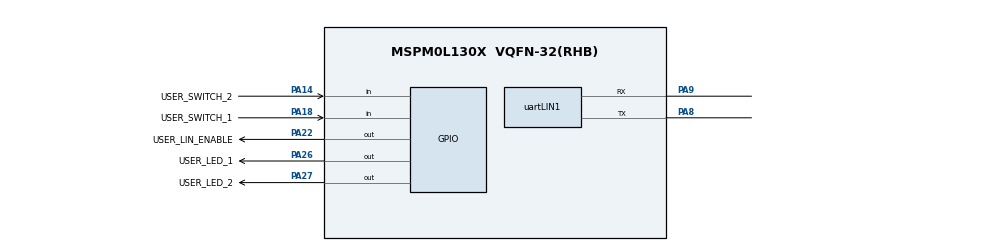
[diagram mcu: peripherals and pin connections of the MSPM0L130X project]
// @cliArgs --device "MSPM0L130X" --package "VQFN-32(RHB)" --part "Default"
// @cliArgs --board /ti/boards/LP_MSPM0L1306 --rtos nortos

/**
 * Import the modules used in this configuration.
 */
const Board  = scripting.addModule("/ti/driverlib/Board");
const GPIO   = scripting.addModule("/ti/driverlib/GPIO", {}, false);
const GPIO1  = GPIO.addInstance();
const GPIO2  = GPIO.addInstance();
const GPIO3  = GPIO.addInstance();
const uartLIN    = scripting.addModule("/ti/driverlib/uartLIN", {}, false);
const uartLIN1   = uartLIN.addInstance();
const SYSCTL = scripting.addModule("/ti/driverlib/SYSCTL");

/**
 * Write custom configuration values to the imported modules.
 */

GPIO1.$name                         = "GPIO_LEDS";
GPIO1.portSegment                   = "Upper";
GPIO1.port                          = "PORTA";
GPIO1.associatedPins.create(2);
GPIO1.associatedPins[0].$name       = "USER_LED_1";
GPIO1.associatedPins[0].assignedPin = "26";
GPIO1.associatedPins[0].pin.$assign = "PA26";
GPIO1.associatedPins[1].$name       = "USER_LED_2";
GPIO1.associatedPins[1].assignedPin = "27";
GPIO1.associatedPins[1].pin.$assign = "PA27";

GPIO2.$name                                 = "GPIO_LIN_ENABLE";
GPIO2.port                                  = "PORTA";
GPIO2.associatedPins[0].$name               = "USER_LIN_ENABLE";
GPIO2.associatedPins[0].assignedPin         = "22";
GPIO2.associatedPins[0].assignedPortSegment = "Upper";
GPIO2.associatedPins[0].pin.$assign         = "PA22";

GPIO3.$name                                 = "GPIO_SWITCHES1";
GPIO3.port                                  = "PORTA";
GPIO3.associatedPins.create(2);
GPIO3.associatedPins[0].$name               = "USER_SWITCH_1";
GPIO3.associatedPins[0].assignedPortSegment = "Upper";
GPIO3.associatedPins[0].assignedPin         = "18";
GPIO3.associatedPins[0].direction           = "INPUT";
GPIO3.associatedPins[0].interruptEn         = true;
GPIO3.associatedPins[0].polarity            = "RISE";
GPIO3.associatedPins[0].pin.$assign         = "PA18";
GPIO3.associatedPins[1].$name               = "USER_SWITCH_2";
GPIO3.associatedPins[1].assignedPin         = "14";
GPIO3.associatedPins[1].assignedPortSegment = "Lower";
GPIO3.associatedPins[1].direction           = "INPUT";
GPIO3.associatedPins[1].interruptEn         = true;
GPIO3.associatedPins[1].internalResistor    = "PULL_UP";
GPIO3.associatedPins[1].polarity            = "FALL";
GPIO3.associatedPins[1].pin.$assign         = "PA14";

uartLIN1.$name                    = "LIN_0";
uartLIN1.targetBaudRate           = 19200;
uartLIN1.tbitVal                  = 9.5;
uartLIN1.enableDMARX              = false;
uartLIN1.enableDMATX              = false;
uartLIN1.enabledInterrupts        = ["RX"];
uartLIN1.peripheral.$assign       = "UART0";
uartLIN1.peripheral.rxPin.$assign = "PA9";
uartLIN1.peripheral.txPin.$assign = "PA8";
